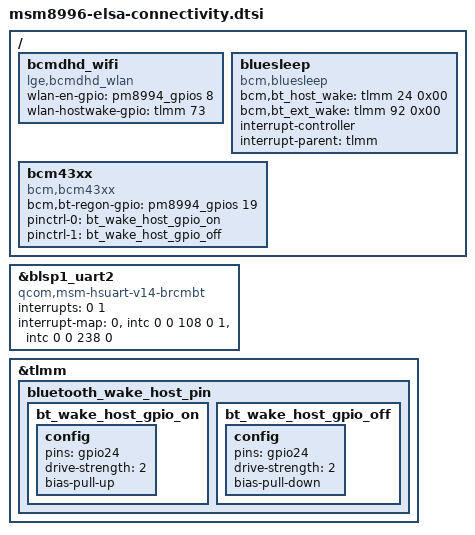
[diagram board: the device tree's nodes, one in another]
/* Copyright (c) 2015, The Linux Foundation. All rights reserved.
 * Copyright (c) 2017, The LineageOS Project. All rights reserved.
 *
 * This program is free software; you can redistribute it and/or modify
 * it under the terms of the GNU General Public License version 2 and
 * only version 2 as published by the Free Software Foundation.
 *
 * This program is distributed in the hope that it will be useful,
 * but WITHOUT ANY WARRANTY; without even the implied warranty of
 * MERCHANTABILITY or FITNESS FOR A PARTICULAR PURPOSE.  See the
 * GNU General Public License for more details.
 */

&blsp1_uart2 {
  compatible = "qcom,msm-hsuart-v14-brcmbt";
	interrupt-names = "core_irq", "bam_irq";
	interrupts = <0 1>;
	interrupt-map = <0 &intc 0 0 108 0
	                 1 &intc 0 0 238 0>;
};

/ {
	/* BCMDHD for Wi-Fi */
	bcmdhd_wifi {
		compatible = "lge,bcmdhd_wlan";
		wlan-en-gpio = <&pm8994_gpios 8 0>;
		wlan-hostwake-gpio = <&tlmm 73 0>;
	};

	bluesleep {
		compatible = "bcm,bluesleep";
		bcm,bt_host_wake = <&tlmm 24 0x00>; /* BT_HOST_WAKE */
		bcm,bt_ext_wake = <&tlmm 92 0x00>; /* BT_DEV_WAKE */
		interrupt-controller;
		interrupt-parent = <&tlmm>;
		//interrupts = <24 0>;
		//interrupt-names = "host_wake";
	};

	bcm43xx {
		compatible = "bcm,bcm43xx";
		bcm,bt-regon-gpio = <&pm8994_gpios 19 0x00>; /* BT_REG_ON */
		pinctrl-names = "bt_wake_host_gpio_on", "bt_wake_host_gpio_off";
		pinctrl-0 = <&bt_wake_host_gpio_on>;
		pinctrl-1 = <&bt_wake_host_gpio_off>;
  };
};

&tlmm {
    /* GPIO_24 : BT_HOST_WAKE */
    bluetooth_wake_host_pin {
			bt_wake_host_gpio_on: bt_wake_host_gpio_on {
				config {
					pins = "gpio24";
					drive-strength = <2>;
					bias-pull-up;
				};
			};

			bt_wake_host_gpio_off: bt_wake_host_gpio_off {
				config {
					pins = "gpio24";
					drive-strength = <2>;
					bias-pull-down;
				};
			};
		};
};
